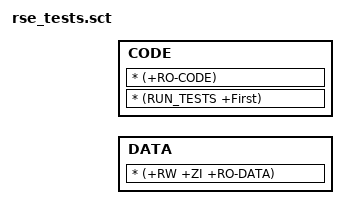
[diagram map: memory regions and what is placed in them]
/*
 * Copyright (c) 2017-2023 Arm Limited. All rights reserved.
 *
 * Licensed under the Apache License, Version 2.0 (the "License");
 * you may not use this file except in compliance with the License.
 * You may obtain a copy of the License at
 *
 *     http://www.apache.org/licenses/LICENSE-2.0
 *
 * Unless required by applicable law or agreed to in writing, software
 * distributed under the License is distributed on an "AS IS" BASIS,
 * WITHOUT WARRANTIES OR CONDITIONS OF ANY KIND, either express or implied.
 * See the License for the specific language governing permissions and
 * limitations under the License.
 */

#include "region_defs.h"

LR_DATA RSE_TESTS_DATA_START {
    DATA RSE_TESTS_DATA_START RSE_TESTS_DATA_SIZE {
        * (+RW +ZI +RO-DATA)
    }
}

LR_CODE RSE_TESTS_CODE_START {
    CODE RSE_TESTS_CODE_START RSE_TESTS_CODE_SIZE {
        * (RUN_TESTS +First)
        * (+RO-CODE)
    }
}
